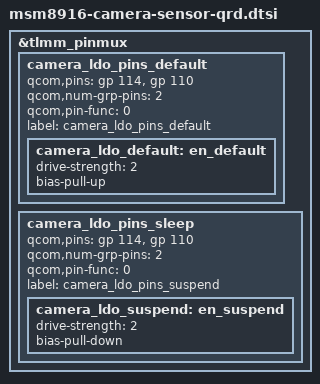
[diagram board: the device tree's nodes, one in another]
/*
 * Copyright (c) 2014, The Linux Foundation. All rights reserved.
 *
 * This program is free software; you can redistribute it and/or modify
 * it under the terms of the GNU General Public License version 2 and
 * only version 2 as published by the Free Software Foundation.
 *
 * This program is distributed in the hope that it will be useful,
 * but WITHOUT ANY WARRANTY; without even the implied warranty of
 * MERCHANTABILITY or FITNESS FOR A PARTICULAR PURPOSE.  See the
 * GNU General Public License for more details.
 */
&tlmm_pinmux {
	camera_ldo_pins_default {
		qcom,pins = <&gp 114>, <&gp 110>;
		qcom,num-grp-pins = <2>;
		qcom,pin-func = <0>;
		label = "camera_ldo_pins_default";
		camera_ldo_default: en_default {
			drive-strength = <2>;
			bias-pull-up;
		};
	};

	camera_ldo_pins_sleep {
		qcom,pins = <&gp 114>, <&gp 110>;
		qcom,num-grp-pins = <2>;
		qcom,pin-func = <0>;
		label = "camera_ldo_pins_suspend";
		camera_ldo_suspend: en_suspend {
			drive-strength = <2>;
			bias-pull-down;
		};
	};
};


